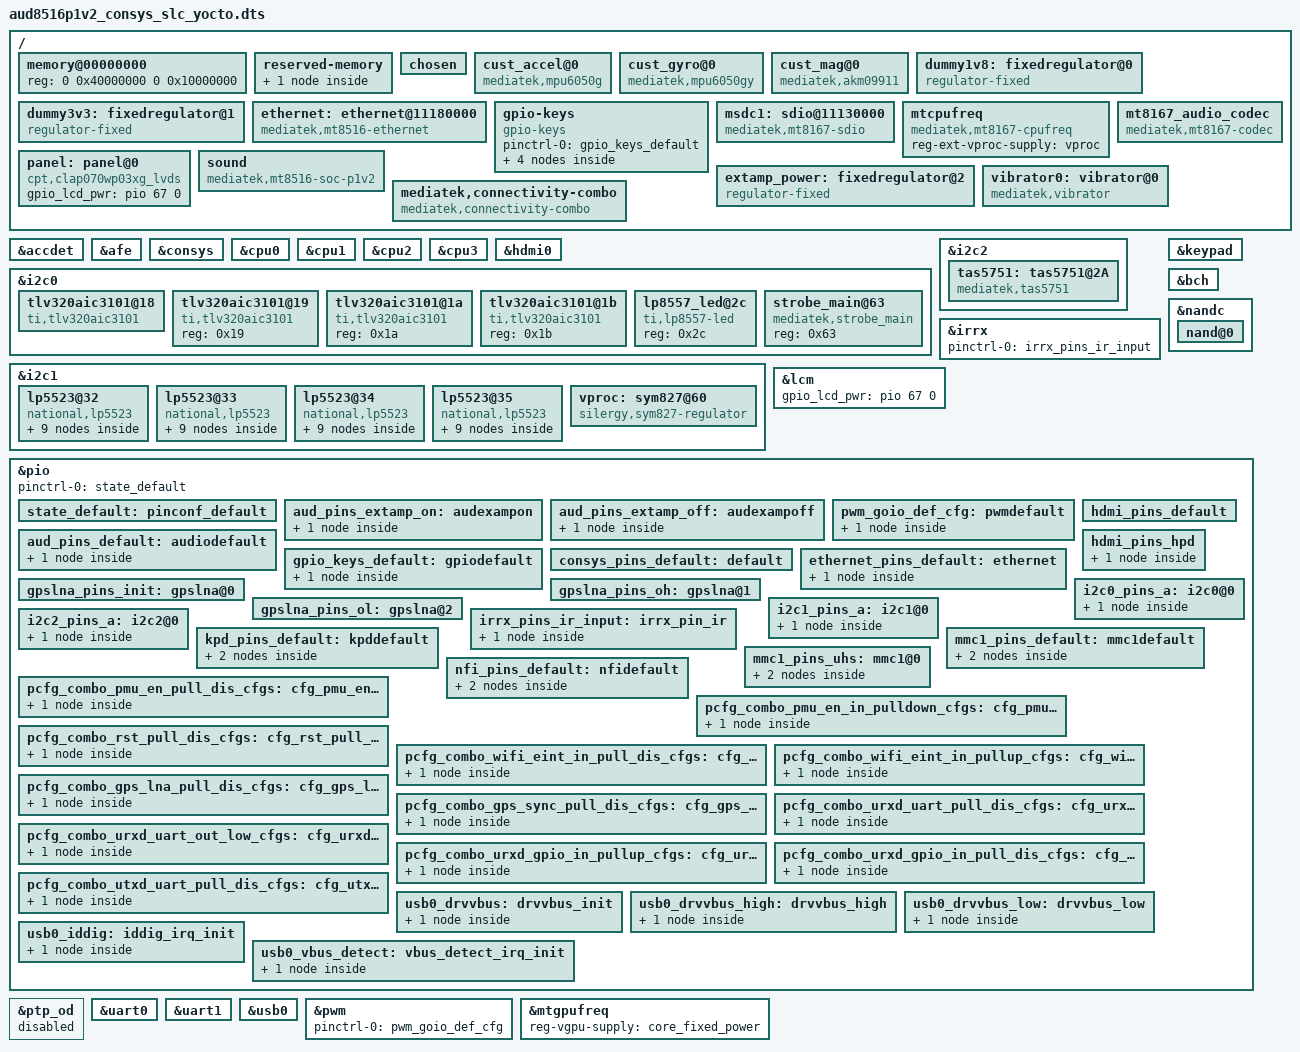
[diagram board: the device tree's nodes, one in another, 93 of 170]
/*
 * Copyright (c) 2014-2015 MediaTek Inc.
 *
 * This program is free software; you can redistribute it and/or modify
 * it under the terms of the GNU General Public License version 2 as
 * published by the Free Software Foundation.
 *
 * This program is distributed in the hope that it will be useful,
 * MERCHANTABILITY or FITNESS FOR A PARTICULAR PURPOSE.  See the
 * GNU General Public License for more details.
 */

/dts-v1/;

#include "mt8167.dtsi"
#include "mt8516-dcdc.dtsi"

/ {
	/*
	IMPORTANT: 	If you modify the memory size,please modify mtee-reserved-memory size together.
					mtee must be located begin with the last 3MB of dram
	*/
	memory@00000000 {
		device_type = "memory";
		reg = <0 0x40000000 0 0x10000000>;
	};
	reserved-memory {
		mtee-reserved-memory {
			compatible = "mediatek,mt8167-mtee-reserved-memory";
			no-map;
			reg = <0 0x4FD00000 0 0x300000>;
		};
	};

	/* chosen */
	chosen {
		bootargs = "console=tty0 console=ttyS0,921600n1 earlycon=uart8250,mmio32,0x11005000 ubi.mtd=8 root=ubi0:aud8516p1v2-consys-slc-rootfs rootfstype=ubifs vmalloc=496M androidboot.hardware=aud8516p1_linux";
	};

/* sensor standardization */
	cust_accel@0 {
		compatible = "mediatek,mpu6050g";
		i2c_num	= <2>;
		i2c_addr = <0x68 0 0 0>;
		direction = <7>;
		power_id = <0xffff>;
		power_vol = <0>;
		firlen = <0>;
		is_batch_supported = <0>;
	};

	cust_gyro@0 {
		compatible = "mediatek,mpu6050gy";
		i2c_num = <2>;
		i2c_addr = <0x68 0 0 0>;
		direction = <7>;
		power_id = <0xffff>;
		power_vol = <0>;
		firlen = <0>;
		is_batch_supported = <0>;
	};

	cust_mag@0 {
		compatible = "mediatek,akm09911";
		i2c_num = <2>;
		i2c_addr = <0x0C 0 0 0>;
		direction = <6>;
		power_id = <0xffff>;
		power_vol = <0>;
		is_batch_supported			= <0>;
	};
/* sensor gpio standization */

	dummy1v8: fixedregulator@0 {
		compatible = "regulator-fixed";
		regulator-name = "mmc_io";
		regulator-min-microvolt = <1800000>;
		regulator-max-microvolt = <1800000>;
		regulator-always-on;
	};

	dummy3v3: fixedregulator@1 {
		compatible = "regulator-fixed";
		regulator-name = "mmc_power";
		regulator-min-microvolt = <3300000>;
		regulator-max-microvolt = <3300000>;
		regulator-always-on;
	};

	ethernet: ethernet@11180000 {
		compatible = "mediatek,mt8516-ethernet";
		reg = <0 0x11180000 0 0x1000>,
		      <0 0x10003400 0 0x1000>;
		interrupts = <GIC_SPI 111 IRQ_TYPE_LEVEL_LOW>;
		eth-gpios = <&pio 34 0>;
		clocks = <&topckgen CLK_TOP_RG_ETH>,
			 <&topckgen CLK_TOP_66M_ETH>,
			 <&topckgen CLK_TOP_133M_ETH>;
		clock-names = "core", "reg", "trans";
		eth-regulator-supply = <&eth_fixed_3v3>;
		pinctrl-names = "default";
		pinctrl-0 = <&ethernet_pins_default>;
		mac-address = [00 00 00 00 00 00];
		/*local-mac-address = [00 0C E7 06 00 00];*/
		status = "okay";
	};

	gpio-keys {
		compatible = "gpio-keys";
		pinctrl-names = "default";
		pinctrl-0 = <&gpio_keys_default>;

		button@0 {
			debounce_interval = <50>;
			/*wakeup-source;*/
			/*gpio-key,wakeup = <1>;*/
			gpios = <&pio 29 1>;
			label = "micmute";
			linux,input-type = <0x1>;
			linux,code = <248>;
		};

		button@1 {
			debounce_interval = <50>;
			wakeup-source;
			gpio-key,wakeup = <1>;
			gpios = <&pio 50 1>;
			label = "powerkey";
			linux,input-type = <0x1>;
			linux,code = <249>;
		};

		button@2 {
			debounce_interval = <50>;
			/*wakeup-source;*/
			/*gpio-key,wakeup = <1>;*/
			gpios = <&pio 51 1>;
			label = "Bluetooth";
			linux,input-type = <0x1>;
			linux,code = <237>;
		};

		button@3 {
			debounce_interval = <50>;
			/*wakeup-source;*/
			/*gpio-key,wakeup = <1>;*/
			gpios = <&pio 67 1>;
			label = "volumedown";
			linux,input-type = <0x1>;
			linux,code = <114>;
		};
	};

	msdc1: sdio@11130000 {
		compatible = "mediatek,mt8167-sdio";
		reg = <0 0x11130000 0 0x1000>;
		interrupts = <GIC_SPI 79 IRQ_TYPE_LEVEL_LOW>;
		clocks = <&topckgen CLK_TOP_MSDC1>,
			 <&topckgen CLK_TOP_AHB_INFRA_SEL>,
			 <&topckgen CLK_TOP_MSDC1_INFRA>;
		clock-names = "sdio-bus", "sdio-src", "sdio-src-cg";
		status = "disabled";
	};

	mtcpufreq {
		compatible = "mediatek,mt8167-cpufreq";
		reg-ext-vproc-supply = <&vproc>;
	};

	mt8167_audio_codec: mt8167_audio_codec {
		compatible = "mediatek,mt8167-codec";
		clocks = <&topckgen CLK_TOP_AUDIO>;
		clock-names = "bus";
		mediatek,afe-regmap = <&afe>;
		mediatek,apmixedsys-regmap = <&apmixedsys>;
		mediatek,pwrap-regmap = <&pwrap>;
		mediatek,speaker-mode = <0>; /* 0(CLASSD) 1(CLASSAB) */
		mediatek,dmic-wire-mode = <1>; /* 0(ONE_WIRE) 1(TWO_WIRE) */
	};

	panel: panel@0 {
		compatible = "cpt,clap070wp03xg_lvds";
		gpio_lcd_pwr = <&pio 67 0>;
	};

	sound: sound {
		compatible = "mediatek,mt8516-soc-p1v2";
		mediatek,platform = <&afe>;
		
		mediatek,hp-spk-amp-warmup-time-us = <40000>;
		pinctrl-names = "default", "extamp_on", "extamp_off";
		pinctrl-0 = <&aud_pins_default>;
		pinctrl-1 = <&aud_pins_extamp_on>;
		pinctrl-2 = <&aud_pins_extamp_off>;
		extamp-supply = <&extamp_power>;

		tas5751-rst-supply = <&cs4382a_fixed_3v3>;
		pcm1861-1p8v-supply = <&pcm1861_fixed_1v8>;
		pcm1861-3p3v-supply = <&pcm1861_fixed_3v3>;
		mediatek,audio-codec = <&tas5751>;
		status = "okay";
	};


	extamp_power: fixedregulator@2 {
		compatible = "regulator-fixed";
		regulator-name = "extamp_power";
		regulator-min-microvolt = <5000000>;
		regulator-max-microvolt = <5000000>;
		gpio = <&pio 33 0>;
		enable-active-high;
	};

	vibrator0:vibrator@0 {
		compatible = "mediatek,vibrator";
		vib_timer = <25>;
		vib_limit = <9>;
		vib_vol= <5>;
	};

	/* Connectivity */
	mediatek,connectivity-combo {
		compatible = "mediatek,connectivity-combo";
		gpio_combo_pmu_en_pin = <&pio 48 0>;	/* GPIO_COMBO_PMU_EN_PIN */
		gpio_combo_rst_pin = <&pio 18 0>;	/* GPIO_COMBO_RST_PIN pin */
		gpio_wifi_eint_pin = <&pio 20 0>;	/* GPIO_WIFI_EINT_PIN */
		gpio_gps_sync_pin = <&pio 4 0>;		/* GPIO_GPS_SYNC_PIN */
		gpio_gps_lna_pin = <&pio 3 0>;		/* GPIO_GPS_LNA_PIN */
		gpio_combo_urxd_pin = <&pio 64 0>;	/* GPIO_COMBO_URXD_PIN */
		gpio_combo_utxd_pin = <&pio 65 0>;	/* GPIO_COMBO_UTXD_PIN */
		pinctrl-names = "gpio_pmu_en_pull_dis",
			"gpio_pmu_en_in_pulldown",
			"gpio_rst_pull_dis",
			"gpio_wifi_eint_in_pull_dis",
			"gpio_wifi_eint_in_pullup",
			"gpio_gps_lna_pull_dis",
			"gpio_gps_sync_pull_dis",
			"gpio_urxd_uart_pull_dis",
			"gpio_urxd_gpio_in_pullup",
			"gpio_urxd_uart_out_low",
			"gpio_urxd_gpio_in_pull_dis",
			"gpio_utxd_uart_pull_dis";
		pinctrl-0 = <&pcfg_combo_pmu_en_pull_dis_cfgs>;
		pinctrl-1 = <&pcfg_combo_pmu_en_in_pulldown_cfgs>;
		pinctrl-2 = <&pcfg_combo_rst_pull_dis_cfgs>;
		pinctrl-3 = <&pcfg_combo_wifi_eint_in_pull_dis_cfgs>;
		pinctrl-4 = <&pcfg_combo_wifi_eint_in_pullup_cfgs>;
		pinctrl-5 = <&pcfg_combo_gps_lna_pull_dis_cfgs>;
		pinctrl-6 = <&pcfg_combo_gps_sync_pull_dis_cfgs>;
		pinctrl-7 = <&pcfg_combo_urxd_uart_pull_dis_cfgs>;
		pinctrl-8 = <&pcfg_combo_urxd_gpio_in_pullup_cfgs>;
		pinctrl-9 = <&pcfg_combo_urxd_uart_out_low_cfgs>;
		pinctrl-10 = <&pcfg_combo_urxd_gpio_in_pull_dis_cfgs>;
		pinctrl-11 = <&pcfg_combo_utxd_uart_pull_dis_cfgs>;
		interrupt-parent = <&pio>;
		interrupts = < 20 IRQ_TYPE_LEVEL_LOW >;	/* WIFI EINT num is 1 active low level-sensitive */
		status = "okay";
	};
};

&accdet {
	interrupts-extended = <&sysirq GIC_SPI 152 IRQ_TYPE_LEVEL_LOW>,
			<&pio 16 IRQ_TYPE_LEVEL_HIGH>;
	eint-debounce = <256000>;
	accdet-gpio = <&pio 16 0>;
	accdet-mic-vol = <7>;
	headset-mode-setting = <0x500 0x500 1 0x1f0 0x800 0x800 0x20>;
	accdet-plugout-debounce = <20>;
	/*1:ACC mode, 2:low cost without in bias, 6:low cost with in bias*/
	accdet-mic-mode = <1>;
	/*0--MD_MAX--UP_MAX--DW_MAX*/
	headset-three-key-threshold = <0 80 220 500>;
	/*0--MD_MAX--VOICE_MAX--UP_MAX--DW_MAX*/
	headset-four-key-threshold = <0 58 121 192 450>;
	status = "okay";
};

&afe {
	/* 0(HDMI) 1(I2S) 2(TDM) */
	mediatek,tdm-out-mode = <1>;
	/* 0(IR1) 1(IRQ2) 4(IRQ7)*/
	mediatek,awb-irq-mode = <4>;
	mediatek,tdm-in-lrck-cycle = <1>;
};

&consys {
	pinctrl-names = "default", "gps_lna_state_init", "gps_lna_state_oh", "gps_lna_state_ol";
	pinctrl-0 = <&consys_pins_default>;
	pinctrl-1 = <&gpslna_pins_init>;
	pinctrl-2 = <&gpslna_pins_oh>;
	pinctrl-3 = <&gpslna_pins_ol>;
	status = "okay";
};

&cpu0 {
};

&cpu1 {
};

&cpu2 {
};

&cpu3 {
};

&hdmi0 {
	pinctrl-names = "default", "hdmi_hpd";
	pinctrl-0 = <&hdmi_pins_default>;
	pinctrl-1 = <&hdmi_pins_hpd>;
	status = "okay";
};

&i2c0 {
	clock-div = <2>;
	pinctrl-names = "default";
	pinctrl-0 = <&i2c0_pins_a>;
	status = "okay";
	
	
		tlv320aic3101@18 {
		compatible = "ti,tlv320aic3101";
		reg = <0x18>;
		rst-gpio = <&pio 40 0>;
		adc-pos = <0>; 
		ref-ch = <2>;
	};

		tlv320aic3101@19 {
		compatible = "ti,tlv320aic3101";
		reg = <0x19>;
	};
		
		tlv320aic3101@1a {
		compatible = "ti,tlv320aic3101";
		reg = <0x1a>;
	};

		tlv320aic3101@1b {
		compatible = "ti,tlv320aic3101";
		reg = <0x1b>;
	};


	lp8557_led@2c {
		compatible = "ti,lp8557-led";
		reg = <0x2c>;
	};

	strobe_main@63 {
		compatible = "mediatek,strobe_main";
		reg = <0x63>;
	};
};

&i2c1 {
	clock-div = <2>;
	pinctrl-names = "default";
	pinctrl-0 = <&i2c1_pins_a>;
	status = "okay";
	lp5523@32{
	compatible = "national,lp5523";
	reg = <0x32>;
	enable-gpio = <&pio 69 0>;
	clock-mode = /bits/ 8 <1>;

	chan0 {
		chan-name = "d1";
		led-cur = /bits/ 8 <0x20>;
		max-cur = /bits/ 8 <0xff>;
	};

	chan1 {
		chan-name = "d2";
		led-cur = /bits/ 8 <0x20>;
		max-cur = /bits/ 8 <0xff>;
	};

	chan2 {
		chan-name = "d3";
		led-cur = /bits/ 8 <0x20>;
		max-cur = /bits/ 8 <0xff>;
	};

	chan3 {
		chan-name = "d4";
		led-cur = /bits/ 8 <0x20>;
		max-cur = /bits/ 8 <0xff>;
	};

	chan4 {
		chan-name = "d5";
		led-cur = /bits/ 8 <0x20>;
		max-cur = /bits/ 8 <0xff>;
	};

	chan5 {
		chan-name = "d6";
		led-cur = /bits/ 8 <0x20>;
		max-cur = /bits/ 8 <0xff>;
	};

	chan6 {
		chan-name = "d7";
		led-cur = /bits/ 8 <0x20>;
		max-cur = /bits/ 8 <0xff>;
	};

	chan7 {
		chan-name = "d8";
		led-cur = /bits/ 8 <0x20>;
		max-cur = /bits/ 8 <0xff>;
	};

	chan8 {
		chan-name = "d9";
		led-cur = /bits/ 8 <0x20>;
		max-cur = /bits/ 8 <0xff>;
	};
	};
	lp5523@33{
	compatible = "national,lp5523";
	reg = <0x33>;
	enable-gpio = <&pio 69 0>;
	clock-mode = /bits/ 8 <1>;

	chan0 {
		chan-name = "d1_1";
		led-cur = /bits/ 8 <0x20>;
		max-cur = /bits/ 8 <0xff>;
	};

	chan1 {
		chan-name = "d1_2";
		led-cur = /bits/ 8 <0x20>;
		max-cur = /bits/ 8 <0xff>;
	};

	chan2 {
		chan-name = "d1_3";
		led-cur = /bits/ 8 <0x20>;
		max-cur = /bits/ 8 <0xff>;
	};
	chan3 {
		chan-name = "d1_4";
		led-cur = /bits/ 8 <0x20>;
		max-cur = /bits/ 8 <0xff>;
	};

	chan4 {
		chan-name = "d1_5";
		led-cur = /bits/ 8 <0x20>;
		max-cur = /bits/ 8 <0xff>;
	};

	chan5 {
		chan-name = "d1_6";
		led-cur = /bits/ 8 <0x20>;
		max-cur = /bits/ 8 <0xff>;
	};

	chan6 {
		chan-name = "d1_7";
		led-cur = /bits/ 8 <0x20>;
		max-cur = /bits/ 8 <0xff>;
	};

	chan7 {
		chan-name = "d1_8";
		led-cur = /bits/ 8 <0x20>;
		max-cur = /bits/ 8 <0xff>;
	};

	chan8 {
		chan-name = "d1_9";
		led-cur = /bits/ 8 <0x20>;
		max-cur = /bits/ 8 <0xff>;
	};
    };
	lp5523@34{
	compatible = "national,lp5523";
	reg = <0x34>;
	enable-gpio = <&pio 69 0>;
	clock-mode = /bits/ 8 <1>;

	chan0 {
		chan-name = "d2_1";
		led-cur = /bits/ 8 <0x20>;
		max-cur = /bits/ 8 <0xff>;
	};

	chan1 {
		chan-name = "d2_2";
		led-cur = /bits/ 8 <0x20>;
		max-cur = /bits/ 8 <0xff>;
	};

	chan2 {
		chan-name = "d2_3";
		led-cur = /bits/ 8 <0x20>;
		max-cur = /bits/ 8 <0xff>;
	};

	chan3 {
		chan-name = "d2_4";
		led-cur = /bits/ 8 <0x20>;
		max-cur = /bits/ 8 <0xff>;
	};

	chan4 {
		chan-name = "d2_5";
		led-cur = /bits/ 8 <0x20>;
		max-cur = /bits/ 8 <0xff>;
	};

	chan5 {
		chan-name = "d2_6";
		led-cur = /bits/ 8 <0x20>;
		max-cur = /bits/ 8 <0xff>;
	};

	chan6 {
		chan-name = "d2_7";
		led-cur = /bits/ 8 <0x20>;
		max-cur = /bits/ 8 <0xff>;
	};

	chan7 {
		chan-name = "d2_8";
		led-cur = /bits/ 8 <0x20>;
		max-cur = /bits/ 8 <0xff>;
	};

	chan8 {
		chan-name = "d2_9";
		led-cur = /bits/ 8 <0x20>;
		max-cur = /bits/ 8 <0xff>;
	};
    };
	lp5523@35{
	compatible = "national,lp5523";
	reg = <0x35>;
	enable-gpio = <&pio 69 0>;
	clock-mode = /bits/ 8 <1>;

	chan0 {
		chan-name = "d3_1";
		led-cur = /bits/ 8 <0x20>;
		max-cur = /bits/ 8 <0xff>;
	};

	chan1 {
		chan-name = "d3_2";
		led-cur = /bits/ 8 <0x20>;
		max-cur = /bits/ 8 <0xff>;
	};

	chan2 {
		chan-name = "d3_3";
		led-cur = /bits/ 8 <0x20>;
		max-cur = /bits/ 8 <0xff>;
	};

	chan3 {
		chan-name = "d3_4";
		led-cur = /bits/ 8 <0x20>;
		max-cur = /bits/ 8 <0xff>;
	};

	chan4 {
		chan-name = "d3_5";
		led-cur = /bits/ 8 <0x20>;
		max-cur = /bits/ 8 <0xff>;
	};

	chan5 {
		chan-name = "d3_6";
		led-cur = /bits/ 8 <0x20>;
		max-cur = /bits/ 8 <0xff>;
	};

	chan6 {
		chan-name = "d3_7";
		led-cur = /bits/ 8 <0x20>;
		max-cur = /bits/ 8 <0xff>;
	};

	chan7 {
		chan-name = "d3_8";
		led-cur = /bits/ 8 <0x20>;
		max-cur = /bits/ 8 <0xff>;
	};

	chan8 {
		chan-name = "d3_9";
		led-cur = /bits/ 8 <0x20>;
		max-cur = /bits/ 8 <0xff>;
	};
    };
	vproc: sym827@60 {
		compatible = "silergy,sym827-regulator";
		reg = <0x60>;
		regulator-name = "vproc";
		regulator-min-microvolt = <600000>;
		regulator-max-microvolt = <1387500>;
		regulator-enable-ramp-delay = <400>;
		regulator-ramp-delay = <8333>;
		regulator-always-on;
		vsel-gpio = <&pio 34 0>;
	};
};

&i2c2 {
	clock-div = <2>;
	pinctrl-names = "default";
	pinctrl-0 = <&i2c2_pins_a>;
	status = "okay";

	tas5751: tas5751@2A {
		compatible = "mediatek,tas5751";
		reg = <0x2A>;
		rst-gpio = <&pio 24 0>;
		pdn-gpio = <&pio 35 0 >;
		tas5751-supply = <&extamp_power>;
	};
};

&irrx {
	pinctrl-names = "default";
	pinctrl-0 = <&irrx_pins_ir_input>;
	status = "okay";
};

&keypad {
	pinctrl-names = "default";
	pinctrl-0 = <&kpd_pins_default>;
	status = "okay";
	mediatek,kpd-key-debounce = <1024>;
	mediatek,kpd-sw-pwrkey = <116>;
	mediatek,kpd-hw-pwrkey = <8>;
	mediatek,kpd-sw-rstkey  = <114>;
	mediatek,kpd-hw-rstkey = <17>;
	mediatek,kpd-use-extend-type = <0>;
	/*HW Keycode [0~71] -> Linux Keycode*/
	mediatek,kpd-hw-map-num = <72>;
	mediatek,kpd-hw-init-map = <115 113 0 0 0 0 0 0 0 0 0 0 0 0 0 0 0 0 0 0 0 0 0 0
			0 0 0 0 0 0 0 0 0 0 0 0 0 0 0 0 0 0 0 0 0 0 0 0
			0 0 0 0 0 0 0 0 0 0 0 0 0 0 0 0 0 0 0 0 0 0 0 0 >;
	mediatek,kpd-pwrkey-eint-gpio = <0>;
	mediatek,kpd-pwkey-gpio-din  = <0>;
	mediatek,kpd-hw-dl-key0 = <0>;
	mediatek,kpd-hw-dl-key1 = <17>;
	mediatek,kpd-hw-dl-key2 = <8>;
	mediatek,kpd-hw-recovery-key = <17>;
	mediatek,kpd-hw-factory-key  = <0>;
};

&lcm {
	gpio_lcd_pwr = <&pio 67 0>;
};

&msdc1 {
	pinctrl-names = "default", "state_uhs";
	pinctrl-0 = <&mmc1_pins_default>;
	pinctrl-1 = <&mmc1_pins_uhs>;
	status = "okay";
	clk_src = <2>;  /*<MSDC30_CLKSRC_200MHZ>*/
	host_function = <2>;
	bus-width = <4>;
	max-frequency = <200000000>;
	cap-sd-highspeed;
	sd-uhs-sdr50;
	sd-uhs-sdr104;
};

&bch {
	status = "okay";
};

&nandc {
	pinctrl-names = "default";
	pinctrl-0 = <&nfi_pins_default>;
	vcc-supply = <&nfi_fixed_3v3>;
	status = "okay";
	nand@0 {
		reg = <0>;
		nand-on-flash-bbt;
		nand-ecc-mode = "hw";
	};
};

&pio {
	pinctrl-names = "default";
	pinctrl-0 = <&state_default>;

	state_default:pinconf_default {
	};


	aud_pins_extamp_on: audexampon {
		pins_cmd_dat {
			pins = <MT8167_PIN_68_MSDC2_CMD__FUNC_GPIO68>;
			slew-rate = <1>;
			output-high;
		};
	};
	aud_pins_extamp_off: audexampoff {
		pins_cmd_dat {
			pins = <MT8167_PIN_68_MSDC2_CMD__FUNC_GPIO68>;
			slew-rate = <1>;
			output-low;
		};
	};
	
pwm_goio_def_cfg: pwmdefault {
		pins_cmd_dat {
			pinmux = <MT8167_PIN_54_DISP_PWM__FUNC_PWM_B>;
			};
};

	aud_pins_default: audiodefault {
		pins_cmd_dat {
			pinmux = <MT8167_PIN_25_EINT25__FUNC_I2S_8CH_MCK>,
				/* <MT8167_PIN_68_MSDC2_CMD__FUNC_I2S_8CH_DO4>,*/
				 <MT8167_PIN_70_MSDC2_DAT0__FUNC_I2S_8CH_DO2>,
				 <MT8167_PIN_71_MSDC2_DAT1__FUNC_I2S_8CH_DO1>,
				 <MT8167_PIN_72_MSDC2_DAT2__FUNC_I2S_8CH_LRCK>,
				 <MT8167_PIN_73_MSDC2_DAT3__FUNC_I2S_8CH_BCK>,
				 <MT8167_PIN_100_CMDAT0__FUNC_TDM_RX_MCK>,
				 <MT8167_PIN_101_CMDAT1__FUNC_TDM_RX_BCK>,
				 <MT8167_PIN_102_CMMCLK__FUNC_TDM_RX_LRCK>,
				 <MT8167_PIN_103_CMPCLK__FUNC_TDM_RX_DI>,
				 <MT8167_PIN_55_I2S_DATA_IN__FUNC_I2S0_DI>,
				 <MT8167_PIN_56_I2S_LRCK__FUNC_I2S0_LRCK>,
				 <MT8167_PIN_57_I2S_BCK__FUNC_I2S0_BCK>,
				 <MT8167_PIN_66_LCM_RST__FUNC_I2S0_MCK>,
				 <MT8167_PIN_68_MSDC2_CMD__FUNC_GPIO68>;
				 drive-strength = <MTK_DRIVE_4mA>;
		};
	};

	gpio_keys_default: gpiodefault {
		pins_cmd_dat {
			pinmux = <MT8167_PIN_29_PWRAP_SPI0_CK__FUNC_GPIO29>,
			<MT8167_PIN_50_SPI_MI__FUNC_GPIO50>,
			<MT8167_PIN_51_SPI_MO__FUNC_GPIO51>,
			<MT8167_PIN_67_DSI_TE__FUNC_GPIO67>;
			slew-rate = <0>;
			bias-pull-up = <MTK_PUPD_SET_R1R0_01>;
			input-enable;
		};
	};
	
	/* CONSYS GPIO Settings - Start */
	consys_pins_default: default {

	};
	/* CONSYS GPIO Settings - End */

	ethernet_pins_default: ethernet {
		pins_ethernet {
			pinmux = <MT8167_PIN_0_EINT0__FUNC_EXT_TXD0>,
				 <MT8167_PIN_1_EINT1__FUNC_EXT_TXD1>,
				 <MT8167_PIN_2_EINT2__FUNC_EXT_TXD2>,
				 <MT8167_PIN_3_EINT3__FUNC_EXT_TXD3>,
				 <MT8167_PIN_4_EINT4__FUNC_EXT_TXC>,
				 <MT8167_PIN_5_EINT5__FUNC_EXT_RXER>,
				 <MT8167_PIN_6_EINT6__FUNC_EXT_RXC>,
				 <MT8167_PIN_7_EINT7__FUNC_EXT_RXDV>,
				 <MT8167_PIN_8_EINT8__FUNC_EXT_RXD0>,
				 <MT8167_PIN_9_EINT9__FUNC_EXT_RXD1>,
				 <MT8167_PIN_10_EINT10__FUNC_EXT_RXD2>,
				 <MT8167_PIN_11_EINT11__FUNC_EXT_RXD3>,
				 <MT8167_PIN_12_EINT12__FUNC_EXT_TXEN>,
				 <MT8167_PIN_37_MRG_SYNC__FUNC_EXT_COL>,
				 <MT8167_PIN_38_MRG_DI__FUNC_EXT_MDIO>,
				 <MT8167_PIN_39_MRG_DO__FUNC_EXT_MDC>;
		};
	};

	/* CONSYS GPIO Settings - Start */
	gpslna_pins_init: gpslna@0 {
	};

	gpslna_pins_oh: gpslna@1 {
	};

	gpslna_pins_ol: gpslna@2 {
	};
	/* CONSYS GPIO Settings - End */

	hdmi_pins_default: hdmi_pins_default {
	};

	hdmi_pins_hpd: hdmi_pins_hpd {
		pins_cmd_dat {
			pins = <MT8167_PIN_122_HTPLG__FUNC_HTPLG>;
			slew-rate = <0>;
			bias-pull-down;
		};
	};

	i2c0_pins_a: i2c0@0 {
		pins1 {
			pinmux = <MT8167_PIN_58_SDA0__FUNC_SDA0_0>,
				 <MT8167_PIN_59_SCL0__FUNC_SCL0_0>;
			bias-disable;
		};
	};

	i2c1_pins_a: i2c1@0 {
		pins1 {
			pinmux = <MT8167_PIN_52_SDA1__FUNC_SDA1_0>,
				 <MT8167_PIN_53_SCL1__FUNC_SCL1_0>;
			bias-disable;
		};
	};

	i2c2_pins_a: i2c2@0 {
		pins1 {
			pinmux = <MT8167_PIN_60_SDA2__FUNC_SDA2_0>,
				 <MT8167_PIN_61_SCL2__FUNC_SCL2_0>;
			bias-disable;
		};
	};
	
	
	irrx_pins_ir_input: irrx_pin_ir {
		pins_cmd_dat {
		pinmux = <MT8167_PIN_36_MRG_CLK__FUNC_IR>;
		bias-disable;
		};
	};

	kpd_pins_default: kpddefault{
		pins_cols {
			pinmux = <MT8167_PIN_42_KPCOL0__FUNC_KPCOL0>,
				<MT8167_PIN_43_KPCOL1__FUNC_KPCOL1>;
			input-enable;
			bias-pull-up = <MTK_PUPD_SET_R1R0_01>;
		};

		pins_rows {
			pinmux = <MT8167_PIN_40_KPROW0__FUNC_KPROW0>;
			output-low;
			bias-disable;
		};
	};

	mmc1_pins_default: mmc1default {
		pins_cmd_dat {
			pinmux = <MT8167_PIN_106_MSDC1_DAT0__FUNC_MSDC1_DAT0>,
				<MT8167_PIN_107_MSDC1_DAT1__FUNC_MSDC1_DAT1>,
				<MT8167_PIN_108_MSDC1_DAT2__FUNC_MSDC1_DAT2>,
				<MT8167_PIN_109_MSDC1_DAT3__FUNC_MSDC1_DAT3>,
				<MT8167_PIN_104_MSDC1_CMD__FUNC_MSDC1_CMD>;
			input-enable;
			drive-strength = <MTK_DRIVE_6mA>;
			bias-pull-up = <MTK_PUPD_SET_R1R0_01>;
		};

		pins_clk {
			pinmux = <MT8167_PIN_105_MSDC1_CLK__FUNC_MSDC1_CLK>;
			drive-strength = <MTK_DRIVE_6mA>;
			bias-pull-down = <MTK_PUPD_SET_R1R0_10>;
		};

		/* SDIO do not need this pin, just remove it */
		/* pins_insert {
			pinmux = <MT8167_PIN_14_EINT14__FUNC_GPIO14>;
			bias-pull-up;
		}; */
	};

	mmc1_pins_uhs: mmc1@0 {
		pins_cmd_dat {
			pinmux = <MT8167_PIN_106_MSDC1_DAT0__FUNC_MSDC1_DAT0>,
				<MT8167_PIN_107_MSDC1_DAT1__FUNC_MSDC1_DAT1>,
				<MT8167_PIN_108_MSDC1_DAT2__FUNC_MSDC1_DAT2>,
				<MT8167_PIN_109_MSDC1_DAT3__FUNC_MSDC1_DAT3>,
				<MT8167_PIN_104_MSDC1_CMD__FUNC_MSDC1_CMD>;
			input-enable;
			drive-strength = <MTK_DRIVE_6mA>;
			bias-pull-up = <MTK_PUPD_SET_R1R0_01>;
		};

		pins_clk {
			pinmux = <MT8167_PIN_105_MSDC1_CLK__FUNC_MSDC1_CLK>;
			drive-strength = <MTK_DRIVE_8mA>;
			bias-pull-down = <MTK_PUPD_SET_R1R0_10>;
		};
	};

	nfi_pins_default: nfidefault {
		pins_dat {
			pinmux = <MT8167_PIN_114_MSDC0_RSTB__FUNC_NLD0>,
				<MT8167_PIN_117_MSDC0_DAT3__FUNC_NLD1>,
				<MT8167_PIN_120_MSDC0_DAT0__FUNC_NLD2>,
				<MT8167_PIN_113_MSDC0_DAT4__FUNC_NLD3>,
				<MT8167_PIN_112_MSDC0_DAT5__FUNC_NLD4>,
				<MT8167_PIN_118_MSDC0_DAT2__FUNC_NLD5>,
				<MT8167_PIN_111_MSDC0_DAT6__FUNC_NLD6>,
				<MT8167_PIN_110_MSDC0_DAT7__FUNC_NLD7>,
				<MT8167_PIN_119_MSDC0_DAT1__FUNC_NLD8>;
			input-enable;
			drive-strength = <MTK_DRIVE_6mA>;
			bias-pull-up;
		};

		pins_cmd {
			pinmux = <MT8167_PIN_14_EINT14__FUNC_NCLE>,
				<MT8167_PIN_17_EINT17__FUNC_NREB>,
				<MT8167_PIN_22_EINT22__FUNC_NRE_C>,
				<MT8167_PIN_23_EINT23__FUNC_NDQS_C>,
				<MT8167_PIN_115_MSDC0_CMD__FUNC_NALE>,
				<MT8167_PIN_116_MSDC0_CLK__FUNC_NWEB>,
				<MT8167_PIN_15_EINT15__FUNC_NCEB1>,
				<MT8167_PIN_16_EINT16__FUNC_NCEB0>,
				<MT8167_PIN_21_EINT21__FUNC_NRNB>;
			drive-strength = <MTK_DRIVE_6mA>;
			bias-pull-up = <MTK_PUPD_SET_R1R0_10>;
		};
	};

/* Connectivity GPIO start */
	pcfg_combo_pmu_en_pull_dis_cfgs:cfg_pmu_en_pull_dis {
		combo_pins {
			pins = <MT8167_PIN_48_SPI_CS__FUNC_GPIO48>;
			bias-disable;
		};
	};

	pcfg_combo_pmu_en_in_pulldown_cfgs:cfg_pmu_en_in_pulldown {
		combo_pins {
			pins = <MT8167_PIN_48_SPI_CS__FUNC_GPIO48>;
			bias-pull-down;
		};
	};

	pcfg_combo_rst_pull_dis_cfgs:cfg_rst_pull_dis {
		combo_pins {
			pins = <MT8167_PIN_18_EINT18__FUNC_GPIO18>;
			bias-disable;
		};
	};

	pcfg_combo_wifi_eint_in_pull_dis_cfgs:cfg_wifi_eint_in_pull_dis {
		combo_pins {
			pins = <MT8167_PIN_20_EINT20__FUNC_GPIO20>;
			slew-rate = <0>;
			bias-disable;
		};
	};

	pcfg_combo_wifi_eint_in_pullup_cfgs:cfg_wifi_eint_in_pullup {
		combo_pins {
			pins = <MT8167_PIN_20_EINT20__FUNC_GPIO20>;
			slew-rate = <0>;
			bias-pull-up = <00>;
		};
	};

	pcfg_combo_gps_lna_pull_dis_cfgs:cfg_gps_lna_pull_dis {
		combo_pins {
			pins = <MT8167_PIN_3_EINT3__FUNC_GPIO3>;
			bias-disable;
		};
	};

	pcfg_combo_gps_sync_pull_dis_cfgs:cfg_gps_sync_pull_dis {
		combo_pins {
			pins = <MT8167_PIN_4_EINT4__FUNC_GPIO4>;
			bias-disable;
		};
	};

	pcfg_combo_urxd_uart_pull_dis_cfgs:cfg_urxd_pull_dis {
		combo_pins {
			pinmux = <MT8167_PIN_64_URXD1__FUNC_URXD1>;
			bias-disable;
		};
	};

	pcfg_combo_urxd_uart_out_low_cfgs:cfg_urxd_out_low {
		combo_pins {
			pinmux = <MT8167_PIN_64_URXD1__FUNC_GPIO64>;
			slew-rate = <1>;
			output-low;
		};
	};

	pcfg_combo_urxd_gpio_in_pullup_cfgs:cfg_urxd_in_pullup {
		combo_pins {
			pinmux = <MT8167_PIN_64_URXD1__FUNC_URXD1>;
			input-enable;
			bias-pull-up;
		};
	};

	pcfg_combo_urxd_gpio_in_pull_dis_cfgs:cfg_urxd_in_pull_dis {
		combo_pins {
			pinmux = <MT8167_PIN_64_URXD1__FUNC_URXD1>;
			input-enable;
			bias-disable;
		};
	};

	pcfg_combo_utxd_uart_pull_dis_cfgs:cfg_utxd_pull_dis {
		combo_pins {
			pinmux = <MT8167_PIN_65_UTXD1__FUNC_UTXD1>;
			bias-disable;
		};
	};
/* Connectivity GPIO end */

/* USB GPIO start */
	usb0_drvvbus: drvvbus_init {
		pins_cmd_dat {
			pinmux = <MT8167_PIN_49_SPI_CK__FUNC_GPIO49>;
			output-low;
		};
	};

	usb0_drvvbus_high: drvvbus_high {
		pins_cmd_dat {
			pinmux = <MT8167_PIN_49_SPI_CK__FUNC_GPIO49>;
			output-high;
		};
	};

	usb0_drvvbus_low: drvvbus_low {
		pins_cmd_dat {
			pinmux = <MT8167_PIN_49_SPI_CK__FUNC_GPIO49>;
			output-low;
		};
	};

	usb0_iddig: iddig_irq_init {
		pins_cmd_dat {
			pinmux = <MT8167_PIN_41_KPROW1__FUNC_GPIO41>;
			bias-pull-up;
		};
	};

	usb0_vbus_detect: vbus_detect_irq_init {
		pins_cmd_dat {
			pinmux = <MT8167_PIN_28_PWRAP_INT__FUNC_GPIO28>;
			bias-disable;
		};
	};
/* USB GPIO end */
};

&ptp_od {
	vproc-supply = <&vproc_fixed_power>;
	vcore-supply = <&core_fixed_power>;
	status = "disabled";
};

&uart0 {
	status="okay";
};

&uart1 {
	status="okay";
};

&usb0 {
	interrupts-extended = <&sysirq GIC_SPI 72 IRQ_TYPE_LEVEL_LOW>;
	pinctrl-names = "iddig_irq_init", "drvvbus_init", "drvvbus_low", "drvvbus_high", "vbus_detect_irq_init";
	pinctrl-0 = <&usb0_iddig>;
	pinctrl-1 = <&usb0_drvvbus>;
	pinctrl-2 = <&usb0_drvvbus_low>;
	pinctrl-3 = <&usb0_drvvbus_high>;
	pinctrl-4 = <&usb0_vbus_detect>;
	status = "okay";
	iddig_gpio = <&pio 41 0>;
	drvvbus_gpio = <&pio 49 0>;
	vbusdetect_gpio = <&pio 28 0>;
};

&pwm {
	pinctrl-names = "default";
	pinctrl-0 = <&pwm_goio_def_cfg>;
	status = "okay";
};

&mtgpufreq {
	reg-vgpu-supply = <&core_fixed_power>;
};
